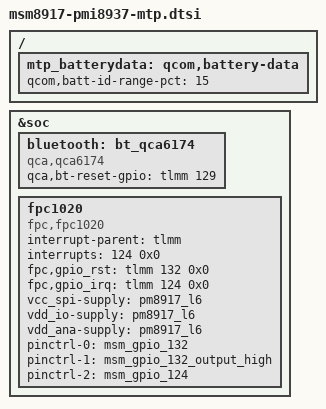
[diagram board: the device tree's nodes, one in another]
/*
 * Copyright (c) 2015-2017, The Linux Foundation. All rights reserved.
 * Copyright (C) 2018 XiaoMi, Inc.
 *
 * This program is free software; you can redistribute it and/or modify
 * it under the terms of the GNU General Public License version 2 and
 * only version 2 as published by the Free Software Foundation.
 *
 * This program is distributed in the hope that it will be useful,
 * but WITHOUT ANY WARRANTY; without even the implied warranty of
 * MERCHANTABILITY or FITNESS FOR A PARTICULAR PURPOSE.  See the
 * GNU General Public License for more details.
 */

#include "msm8917-mtp.dtsi"
#include "msm8917-audio-mtp.dtsi"

&soc {
	bluetooth: bt_qca6174 {
		compatible = "qca,qca6174";
		qca,bt-reset-gpio = <&tlmm 129 0>; /* BT_EN */
	};

	fpc1020 {
		status = "ok";
		compatible = "fpc,fpc1020";
		interrupt-parent = <&tlmm>;
		interrupts = <124 0x0>;
		fpc,gpio_rst    = <&tlmm 132 0x0>;
		fpc,gpio_irq    = <&tlmm 124 0x0>;

		vcc_spi-supply  = <&pm8917_l6>;
		vdd_io-supply   = <&pm8917_l6>;
		vdd_ana-supply  = <&pm8917_l6>;

		pinctrl-names = "fpc1020_reset_reset",
			"fpc1020_reset_active",
			"fpc1020_irq_active";

		pinctrl-0 = <&msm_gpio_132>;
		pinctrl-1 = <&msm_gpio_132_output_high>;
		pinctrl-2 = <&msm_gpio_124>;
	};
};

/{
	mtp_batterydata: qcom,battery-data {
		qcom,batt-id-range-pct = <15>;
		#include "batterydata-itech-3000mah.dtsi"
		#include "batterydata-ascent-3450mAh.dtsi"
	};
};
